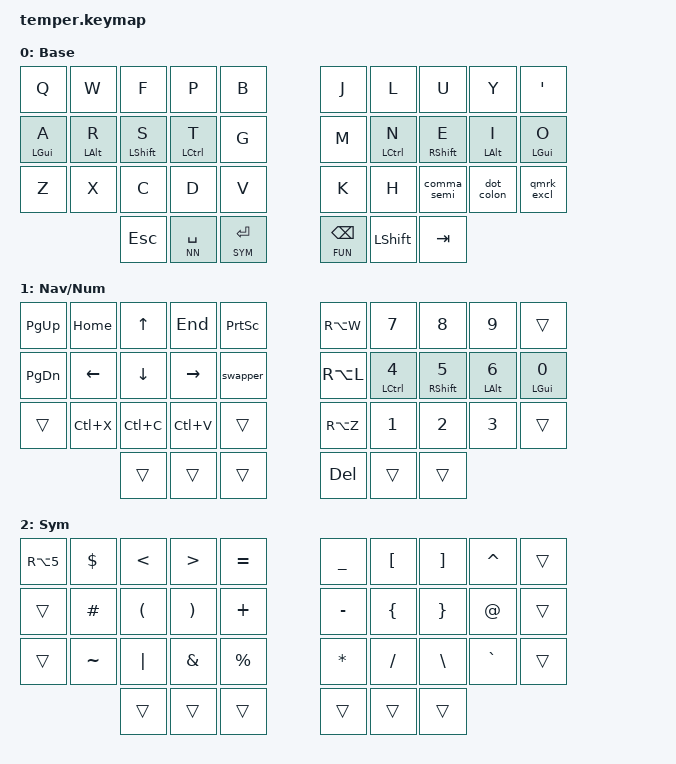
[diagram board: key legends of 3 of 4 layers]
/*
 * Copyright (c) 2020 The ZMK Contributors
 *
 * SPDX-License-Identifier: MIT
 */

#include <behaviors.dtsi>
#include <dt-bindings/zmk/keys.h>
#include <dt-bindings/zmk/bt.h>
#include <dt-bindings/zmk/outputs.h>

#define DEFAULT 0
#define NN 1
#define SYM 2
#define FUN 3

# define ______ &trans

/ {
    behaviors {
        bspc_del: backspace_delete {
            compatible = "zmk,behavior-mod-morph";
            #binding-cells = <0>;
            bindings = <&kp BACKSPACE>, <&kp DELETE>;
            mods = <(MOD_LSFT|MOD_RSFT)>;
            keep-mods = <(MOD_RSFT)>;
        };
        super_bspc: super_backspace {
            compatible = "zmk,behavior-mod-morph";
            #binding-cells = <0>;
            bindings = <&kp BACKSPACE>, <&kp LA(BACKSPACE)>;
            mods = <(MOD_LSFT|MOD_RSFT)>;
        };
        smart_shft: smart_shift {
            compatible = "zmk,behavior-mod-morph";
            #binding-cells = <0>;
            bindings = <&kp LSHFT>, <&caps_word>;
            mods = <(MOD_LSFT)>;
        };
        comma_semi: comma_semi {
            compatible = "zmk,behavior-mod-morph";
            #binding-cells = <0>;
            bindings = <&kp COMMA>, <&kp SEMI>;
            mods = <(MOD_LSFT)>;
        };
        dot_colon: dot_colon {
            compatible = "zmk,behavior-mod-morph";
            #binding-cells = <0>;
            bindings = <&kp DOT>, <&kp COLON>;
            mods = <(MOD_LSFT)>;
        };
        qmrk_excl: qmrk_excl {
            compatible = "zmk,behavior-mod-morph";
            #binding-cells = <0>;
            bindings = <&kp QMARK>, <&kp EXCL>;
            mods = <(MOD_LSFT)>;
        };
        slh_morph: slh_morph {
            compatible = "zmk,behavior-mod-morph";
            #binding-cells = <0>;
            bindings = <&kp FSLH>, <&kp BSLH>;
            mods = <(MOD_LSFT)>;
        };
        amps_morph: amps_morph {
            compatible = "zmk,behavior-mod-morph";
            #binding-cells = <0>;
            bindings = <&kp AMPS>, <&kp PIPE>;
            mods = <(MOD_LSFT)>;
        };
        hm: hm {
            compatible = "zmk,behavior-hold-tap";
            label = "HM";
            bindings = <&kp>, <&kp>;
    
            #binding-cells = <2>;
            quick-tap-ms = <170>;
            tapping-term-ms = <190>;
            global-quick-tap;
            flavor = "tap-preferred";
        };

        hml: hml {
            compatible = "zmk,behavior-hold-tap";
            label = "HML";
            bindings = <&kp>, <&kp>;
    
            #binding-cells = <2>;
            tapping-term-ms = <280>;
            quick-tap-ms = <175>;
            require-prior-idle-ms = <150>;
            flavor = "balanced";
            hold-trigger-on-release;
            hold-trigger-key-positions = <0 1 2 3 4 20 21 22 23 24 14 30 31 32 33 34 35 25 15 5 6 16 26 27 17 7 8 18 28 29 19 9>;
        };

        hmr: hmr {
            compatible = "zmk,behavior-hold-tap";
            label = "HMR";
            bindings = <&kp>, <&kp>;
    
            #binding-cells = <2>;
            tapping-term-ms = <280>;
            quick-tap-ms = <175>;
            require-prior-idle-ms = <150>;
            flavor = "balanced";
            hold-trigger-on-release;
            hold-trigger-key-positions = <0 10 20 21 1 11 12 2 3 4 24 14 13 23 22 30 31 32 33 34 35 25 26 28 27 29 9 8 7 6 5 15>;
        };

        swapper: swapper {
            compatible = "zmk,behavior-tri-state";
            #binding-cells = <0>;
            bindings = <&kt LALT>, <&kp TAB>, <&kt LALT>;
        };
    };
        keymap {
                compatible = "zmk,keymap";

                default_layer {
                        bindings = <
// ╭─────────────┬─────────────┬─────────────┬─────────────┬─────────────╮   ╭─────────────┬─────────────┬─────────────┬─────────────┬─────────────╮
        &kp Q         &kp W         &kp F         &kp P         &kp B             &kp J         &kp L         &kp U         &kp Y       &kp APOS   
// ├─────────────┼─────────────┼─────────────┼─────────────┼─────────────┤   ├─────────────┼─────────────┼─────────────┼─────────────┼─────────────┤
        &hml LGUI A   &hml LALT R   &hml LSHFT S  &hml LCTRL T  &kp G             &kp M        &hmr LCTRL N  &hmr RSHFT E  &hmr LALT I   &hmr LGUI O
// ├─────────────┼─────────────┼─────────────┼─────────────┼─────────────┤   ├─────────────┼─────────────┼─────────────┼─────────────┼─────────────┤
        &kp Z         &kp X         &kp C         &kp D         &kp V             &kp K         &kp H      &comma_semi    &dot_colon    &qmrk_excl
// ╰─────────────┴─────────────┼─────────────┼─────────────┼─────────────┤   ├─────────────┼─────────────┼─────────────┼─────────────┴─────────────╯
                                   &kp ESC      &lt NN SPACE    &lt SYM RET       &lt FUN BSPC  &kp LSHFT  &kp TAB
//                             ╰─────────────┴─────────────┴─────────────╯   ╰─────────────┴─────────────┴─────────────╯
                        >;

                        display-name = "Base";
                };

                nn_layer {
                        bindings = <
// ╭─────────────┬─────────────┬─────────────┬─────────────┬─────────────╮   ╭─────────────┬─────────────┬─────────────┬─────────────┬─────────────╮
    &kp PAGE_UP       &kp HOME      &kp UP        &kp END     &kp PSCRN         &kp RA(W)       &kp N7      &kp N8       &kp N9        ______
// ├─────────────┼─────────────┼─────────────┼─────────────┼─────────────┤   ├─────────────┼─────────────┼─────────────┼─────────────┼─────────────┤
    &kp PAGE_DOWN     &kp LEFT      &kp DOWN      &kp RIGHT   &swapper         &kp RA(L)      &hmr LCTRL N4   &hmr RSHFT N5  &hmr LALT N6 &hmr LGUI N0
// ├─────────────┼─────────────┼─────────────┼─────────────┼─────────────┤   ├─────────────┼─────────────┼─────────────┼─────────────┼─────────────┤
        ______        &kp LC(X)     &kp LC(C)    &kp LC(V)     ______          &kp RA(Z)        &kp N1       &kp N2       &kp N3        ______
// ╰─────────────┴─────────────┼─────────────┼─────────────┼─────────────┤   ├─────────────┼─────────────┼─────────────┼─────────────┴─────────────╯
                                    ______        ______        ______          &kp DEL        ______        ______
//                             ╰─────────────┴─────────────┴─────────────╯   ╰─────────────┴─────────────┴─────────────╯
                        >;
                        
                        display-name = "Nav/Num";
                };
                
                sym_layer {
                        bindings = <
// ╭─────────────┬─────────────┬─────────────┬─────────────┬─────────────╮   ╭─────────────┬─────────────┬─────────────┬─────────────┬─────────────╮
      &kp RA(N5)       &kp DLLR       &kp LT      &kp GT     &kp EQUAL          &kp UNDER       &kp LBKT        &kp RBKT     &kp CARET      ______
// ├─────────────┼─────────────┼─────────────┼─────────────┼─────────────┤   ├─────────────┼─────────────┼─────────────┼─────────────┼─────────────┤
      ______      &kp HASH      &kp LPAR      &kp RPAR         &kp PLUS         &kp MINUS       &kp LBRC        &kp RBRC        &kp AT      ______
// ├─────────────┼─────────────┼─────────────┼─────────────┼─────────────┤   ├─────────────┼─────────────┼─────────────┼─────────────┼─────────────┤
      ______     &kp TILDE       &kp PIPE      &kp AMPS       &kp PRCNT          &kp STAR      &kp FSLH        &kp BSLH      &kp GRAVE       ______
// ╰─────────────┴─────────────┼─────────────┼─────────────┼─────────────┤   ├─────────────┼─────────────┼─────────────┼─────────────┴─────────────╯
                                    ______        ______        ______            ______        ______        ______
//                             ╰─────────────┴─────────────┴─────────────╯   ╰─────────────┴─────────────┴─────────────╯
                        >;
                        
                        display-name = "Sym";
                };

                fun_layer {
                        bindings = <
// ╭─────────────┬─────────────┬─────────────┬─────────────┬─────────────╮   ╭─────────────┬─────────────┬─────────────┬─────────────┬─────────────╮
     &bt BT_CLR    &kp C_VOL_UP   ______      &bootloader         &bootloader    &kp F7        &kp F8        &kp F9       &kp F12
// ├─────────────┼─────────────┼─────────────┼─────────────┼─────────────┤   ├─────────────┼─────────────┼─────────────┼─────────────┼─────────────┤
      ______        &kp C_PREV    &kp C_VOL_DN   &kp C_NEXT  ______               ______        &kp F4        &kp F5        &kp F6       &kp F11
// ├─────────────┼─────────────┼─────────────┼─────────────┼─────────────┤   ├─────────────┼─────────────┼─────────────┼─────────────┼─────────────┤
     &bt BT_SEL 0  &bt BT_SEL 1  &bt BT_SEL 2  &bt BT_SEL 3  &bt BT_SEL 4         ______        &kp F1        &kp F2        &kp F3       &kp F10
// ╰─────────────┴─────────────┼─────────────┼─────────────┼─────────────┤   ├─────────────┼─────────────┼─────────────┼─────────────┴─────────────╯
                                    ______        &kp C_PP        ______            ______        ______        ______
//                             ╰─────────────┴─────────────┴─────────────╯   ╰─────────────┴─────────────┴─────────────╯
                        >;
                        
                        display-name = "Fun";
                };
        };
};
